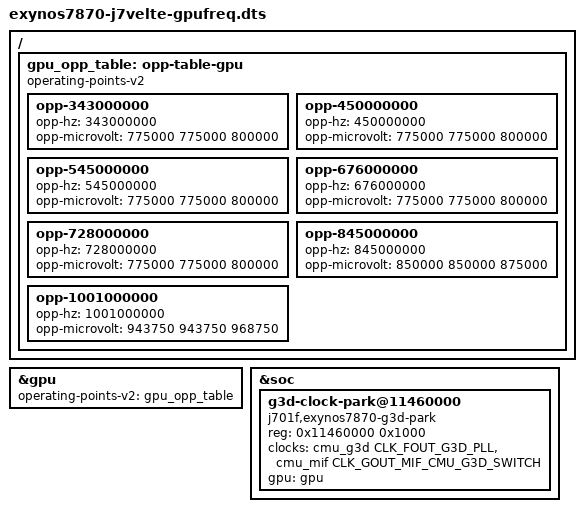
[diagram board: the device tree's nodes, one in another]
// SPDX-License-Identifier: GPL-2.0-only
/* Written by Claude 2026-10-09. Extra tree plus GPU frequency scaling
 * (kernel/patches/linux-g3d-exynos7870-scaling.patch).
 *
 * The OPP frequencies are the vendor GPU steps recorded for this phone
 * (kernel/j701f-gpu-evidence.json). Voltages: the vendor values start at
 * 600 mV, but BUCK2 is at 775 mV when mainline boots and under the vendor
 * kernel it also moved with CPU frequency, so it may feed more than the GPU.
 * No OPP here goes below 775 mV; the two fastest steps use the vendor value
 * plus 12.5 mV. Scaling stays off until the parking driver's max_khz is raised.
 */
#include "exynos7870-j7velte-extra.dts"

/ {
    gpu_opp_table: opp-table-gpu {
        compatible = "operating-points-v2";

        opp-343000000 { opp-hz = /bits/ 64 <343000000>; opp-microvolt = <775000 775000 800000>; };
        opp-450000000 { opp-hz = /bits/ 64 <450000000>; opp-microvolt = <775000 775000 800000>; };
        opp-545000000 { opp-hz = /bits/ 64 <545000000>; opp-microvolt = <775000 775000 800000>; };
        opp-676000000 { opp-hz = /bits/ 64 <676000000>; opp-microvolt = <775000 775000 800000>; };
        opp-728000000 { opp-hz = /bits/ 64 <728000000>; opp-microvolt = <775000 775000 800000>; };
        opp-845000000 { opp-hz = /bits/ 64 <845000000>; opp-microvolt = <850000 850000 875000>; };
        opp-1001000000 { opp-hz = /bits/ 64 <1001000000>; opp-microvolt = <943750 943750 968750>; };
    };
};

&gpu {
    operating-points-v2 = <&gpu_opp_table>;
};

&soc {
    g3d-clock-park@11460000 {
        compatible = "j701f,exynos7870-g3d-park";
        reg = <0x11460000 0x1000>;
        clocks = <&cmu_g3d CLK_FOUT_G3D_PLL>, <&cmu_mif CLK_GOUT_MIF_CMU_G3D_SWITCH>;
        clock-names = "pll", "switch";
        gpu = <&gpu>;
    };
};
